# nrf7140_radiocore register map
Vendor: Nordic Semiconductor; Series: nRF71; File version: 1
CPU: CM33 r0p4, little endian, MPU, FPU, 3 interrupt priority bits, 480 interrupts, 8 SAU regions
Registers are 32-bit, read-write, reset 0x0 unless marked. A register's access mark holds for its fields unless they carry their own. Offsets are from the block's base; [hi:lo] are bit positions; lines under a group give offsets from that group; {n}, {i} and the like mark numbered series.

## GLOBAL_RAMC122_NS — RAM Controller 0
Base 0x4F8DA000
Same registers: GLOBAL_RAMC123_NS 0x4F8DD000, GLOBAL_RAMC122_S 0x5F8DA000, GLOBAL_RAMC123_S 0x5F8DD000
0x500 WAITSTATES — Waitstates for read operations.
  [0] WAITSTATES — Number of waitstates for a read from the RAM.

## GLOBAL_COEXC_NS — Coexistence controller 0
Base 0x4F92E000
Same registers: GLOBAL_COEXC_S 0x5F92E000
{0x400+0x20*i} CCMALLOW[{i}] (i=0..5) group — Unspecified
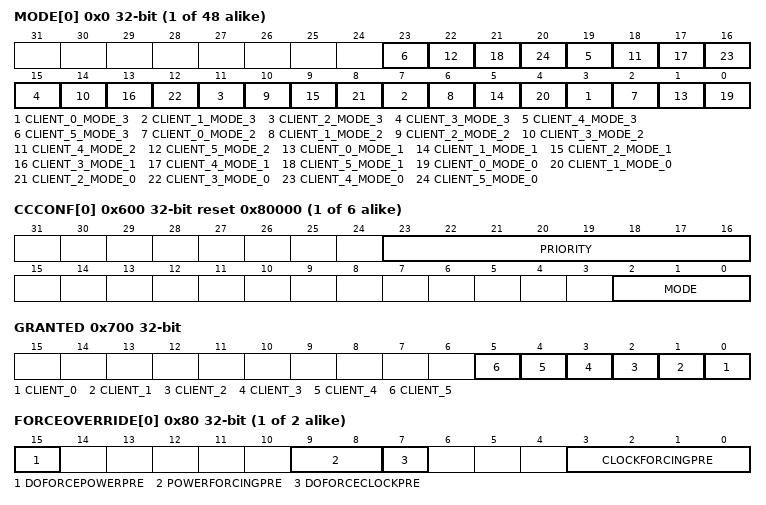
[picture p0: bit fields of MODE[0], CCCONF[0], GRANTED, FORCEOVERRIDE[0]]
  {0x0+4j} MODE[{j}] (j=0..7) — Description collection: Coexistence client mode allow configuration for mode [o] in client [n]
    [all] fields
      0=NotAllowed (Coexistence not allowed); 1=Allow (Coexistence allowed)
    [4n+3] CLIENT_{n}_MODE_3 (n=0..5) — Coexistence allowed configuration for mode [3] in client [{n}]
    [4n+2] CLIENT_{n}_MODE_2 (n=0..5) — Coexistence allowed configuration for mode [2] in client [{n}]
    [4n+1] CLIENT_{n}_MODE_1 (n=0..5) — Coexistence allowed configuration for mode [1] in client [{n}]
    [4n] CLIENT_{n}_MODE_0 (n=0..5) — Coexistence allowed configuration for mode [0] in client [{n}]
{0x600+4i} CCCONF[{i}] (i=0..5) reset 0x80000 — Description collection: Configuration of coexistence client [n]
  [23:16] PRIORITY — Priority of the coexistence client [n]
  [2:0] MODE — Coexistence mode of the client [m]
{0x640+4i} TURNAROUND[{i}] (i=0..5) reset 0x280 — Description collection: Turnaround time for the coexistence client [n]
  [11:0] CLOCKCYCLES — Number of clock cycles
0x700 GRANTED ro — Granted status of the shared resource
  [n] CLIENT_{n} (n=0..5) — Granted status coexistence client [{n}]
    0=NotGranted (Shared resource is not granted for coexistence client [{n}]); 1=Granted (Shared resource is granted for coexistence client [{n}])
0xC00 PCGCSLAVE group — Unspecified
  {0x0+4j} PENALTY[{j}] (j=0..1) reset 0xFFFFFFFC — Description collection: Penalty level for power/clock pair n. When FULL_PCP_ZERO feature is not supported, PENALTY[0] address overlaps the PENALTY0 address and register description for PENALTY[0] is not valid.
    [1:0] PENALTY — Penalty level
  0x00 PENALTY0 (alternate view of PENALTY[*]) — Penalty level for power/clock pair 0. The register description is valid only when FULL_PCP_ZERO feature is not supported
    [1:0] PENALTY ro — Penalty level
  {0x80+4j} FORCEOVERRIDE[{j}] (j=0..1) — Description collection: Force override of power/clock pair n.
    [15] DOFORCEPOWERPRE, [9:8] POWERFORCINGPRE, [7] DOFORCECLOCKPRE, [3:0] CLOCKFORCINGPRE

## GLOBAL_GPIOINTERNAL_NS — GPIO Internal 0
Base 0x4F939E00
Same registers: GLOBAL_GPIOINTERNAL_S 0x5F939E00
0x40 LATCHCLRWAITCNT reset 0x2 — Select the number of wait cycles inserted on the bus when a LATCH register is cleared.
  [1:0] LATCHCLRWAITCNT
0x44 FORCELDETECTLOWCNT reset 0x8 — Select the number of cycles that LDETECT is forced low after clearing a LATCH register.
  [3:0] FORCELDETECTLOWCNT
0x48 RESET — Reset all GPIO registers.
  [0] RESET
    1=RESET (Trigger reset); 0=NA (No effect)
0x4C SENSECONFIGCHANGECNT reset 0x3 — Selects the number of cycles before the SENSE configuration takes effect when it is changed. Setting this register lower than the reset value can lead to unwanted LATCH set when SENSE and INPUT fields (PIN[n].CNF) are changed simultaneously.
  [2:0] SENSECONFIGCHANGECNT — Selects the number of cycles before the SENSE configuration takes effect when it is changed.
0x160 PCGC group — Unspecified
  0x00 TURNOFFAUTOCLOCKSOURCEREQ ro — No functionality
  {0x20+4j} PENALTY[{j}] (j=0..4) ro — Description collection: Penalty level for power/clock pair n
    [7:0] PENALTY — Penalty level
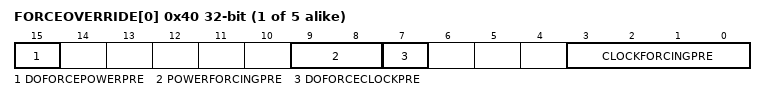
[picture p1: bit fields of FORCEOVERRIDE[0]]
  {0x40+4j} FORCEOVERRIDE[{j}] (j=0..4) ro — Description collection: Force override of power/clock pair n
    [15] DOFORCEPOWERPRE, [9:8] POWERFORCINGPRE, [7] DOFORCECLOCKPRE, [3:0] CLOCKFORCINGPRE
